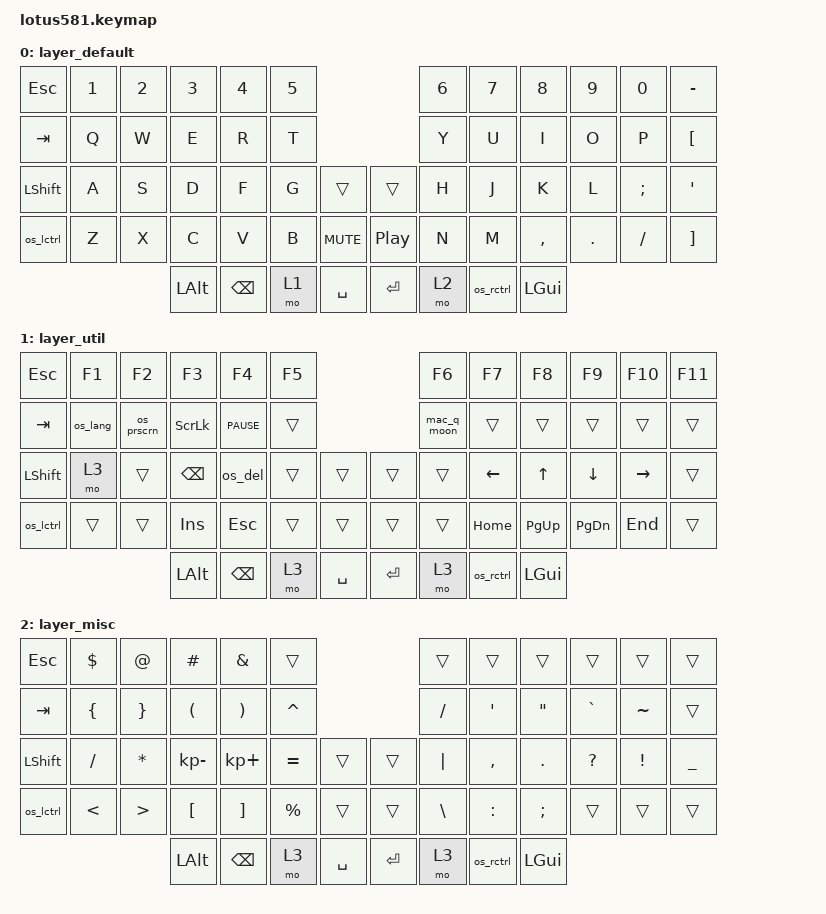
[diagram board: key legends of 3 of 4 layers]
/*
 * Copyright (c) 2022 The ZMK Contributors
 *
 * SPDX-License-Identifier: MIT
 */

#include <behaviors.dtsi>
#include <os_layer.dtsi>
#include <dt-bindings/zmk/keys.h>
#include <dt-bindings/zmk/bt.h>
#include <dt-bindings/zmk/outputs.h>
#include <dt-bindings/zmk/rgb.h>
#include <dt-bindings/led/led.h>
#include <dt-bindings/zmk/os_layer_defines.h>

/ {
    macros {
        sw_p_w: ctrl_shift_l_macro {
            compatible = "zmk,behavior-macro";
            #binding-cells = <0>;
            bindings = <&macro_press &kp LCTRL &kp LSHIFT>,
                       <&macro_tap &kp L>,
                       <&macro_release &kp LCTRL &kp LSHIFT>;
        };

        sw_n_w: ctrl_shift_k_macro {
            compatible = "zmk,behavior-macro";
            #binding-cells = <0>;
            bindings = <&macro_press &kp LCTRL &kp LSHIFT>,
                       <&macro_tap &kp K>,
                       <&macro_release &kp LCTRL &kp LSHIFT>;
        };

        mac_prscrn: mac_prscrn_macro {
            compatible = "zmk,behavior-macro";
            #binding-cells = <0>;
            bindings = <&macro_press &kp LEFT_GUI &kp LSHIFT>,
                       <&macro_tap &kp N5>,
                       <&macro_release &kp LEFT_GUI &kp LSHIFT>;
        };

        mac_del: mac_del_macro {
            compatible = "zmk,behavior-macro";
            #binding-cells = <0>;
            bindings = <&macro_press &kp LEFT_GUI>,
                       <&macro_tap &kp BSPC>,
                       <&macro_release &kp LEFT_GUI>;

        };

        mac_lang: mac_lang_macro {
            compatible = "zmk,behavior-macro";
            #binding-cells = <0>;
            bindings = <&macro_press &kp LCTRL>,
                       <&macro_tap &kp SPACE>,
                       <&macro_release &kp LCTRL>;
        };

        other_lang: other_lang_macro {
            compatible = "zmk,behavior-macro";
            #binding-cells = <0>;
            bindings = <&macro_press &kp LSHFT>,
                       <&macro_tap &kp LALT>,
                       <&macro_release &kp LSHFT>;
        };

        mac_q_moon: mac_q_moon_macro {
            compatible = "zmk,behavior-macro";
            #binding-cells = <0>;
            bindings = <&macro_press &kp LCTRL &kp LSHFT &kp LALT>,
                       <&macro_tap &kp Q>,
                       <&macro_release &kp LCTRL &kp LSHFT &kp LALT>;
        };
    };

    behaviors {
        rgb_encoder: rgb_encoder {
            compatible = "zmk,behavior-sensor-rotate";
            #sensor-binding-cells = <0>;
            bindings = <&rgb_ug RGB_BRI>, <&rgb_ug RGB_BRD>;
        };

        os_lctrl: os_lctrl {
            compatible = "zmk,behavior-os-mod";
            #binding-cells = <0>;
            bindings = <&os_choose KP_OS_OTHER &kp LCTRL>,
                        <&os_choose KP_OS_MAC &kp LEFT_GUI>;
        };

        os_rctrl: os_rctrl {
            compatible = "zmk,behavior-os-mod";
            #binding-cells = <0>;
            bindings = <&os_choose KP_OS_OTHER &kp RSHIFT>,
                        <&os_choose KP_OS_MAC &kp LCTRL>;
        };

        os_prscrn: os_prscrn {
            compatible = "zmk,behavior-os-mod";
            #binding-cells = <0>;
            bindings = <&os_choose KP_OS_OTHER &kp PSCRN>,
                        <&os_choose KP_OS_MAC &mac_prscrn>;
        };

        os_del: os_del {
            compatible = "zmk,behavior-os-mod";
            #binding-cells = <0>;
            bindings = <&os_choose KP_OS_OTHER &kp DELETE>,
                        <&os_choose KP_OS_MAC &mac_del>;
        };

        os_lang: os_lang {
            compatible = "zmk,behavior-os-mod";
            #binding-cells = <0>;
            bindings = <&os_choose KP_OS_OTHER &other_lang>,
                        <&os_choose KP_OS_MAC &mac_lang>;
        };
    };

    keymap {
        compatible = "zmk,keymap";

        layer_default {
            bindings = <
&kp ESC   &kp N1 &kp N2   &kp N3     &kp N4    &kp N5                               &kp N6    &kp N7      &kp N8    &kp N9   &kp N0   &kp MINUS
&kp TAB   &kp Q  &kp W    &kp E      &kp R     &kp T                                &kp Y     &kp U       &kp I     &kp O    &kp P    &kp LEFT_BRACKET
&kp LSHFT &kp A  &kp S    &kp D      &kp F     &kp G      &trans         &trans     &kp H     &kp J       &kp K     &kp L    &kp SEMI &kp SINGLE_QUOTE
&os_lctrl &kp Z  &kp X    &kp C      &kp V     &kp B      &kp K_MUTE     &kp C_PP   &kp N     &kp M       &kp COMMA &kp DOT  &kp SLASH &kp RIGHT_BRACKET
                          &kp LALT   &kp BSPC  &mo 1 &kp SPACE     &kp ENTER  &mo 2  &os_rctrl  &kp LEFT_GUI
            >;

            sensor-bindings = <&inc_dec_kp &sw_p_w &sw_n_w &inc_dec_kp DOWN_ARROW UP_ARROW>;
        };

         layer_util {
            bindings = <
&kp ESC   &kp F1    &kp F2    &kp F3    &kp F4    &kp F5                                &kp F6    &kp F7    &kp F8    &kp F9    &kp F10   &kp F11
&kp TAB   &os_lang    &os_prscrn &kp SLCK  &kp C_PAUSE &trans                                &mac_q_moon    &trans    &trans    &trans    &trans    &trans
&kp LSHFT &mo 3     &trans    &kp BSPC  &os_del &trans   &trans            &trans    &trans    &kp LEFT  &kp UP    &kp DOWN  &kp RIGHT &trans
&os_lctrl &trans    &trans    &kp INSERT &kp ESCAPE &trans  &trans            &trans    &trans    &kp HOME  &kp PAGE_UP &kp PAGE_DOWN &kp END &trans
                              &kp LALT  &kp BSPC  &mo 3     &kp SPACE         &kp ENTER &mo 3     &os_rctrl &kp LEFT_GUI
            >;

            sensor-bindings = <&inc_dec_kp C_VOL_DN C_VOL_UP &inc_dec_kp C_PREV C_NEXT>;
        };

        layer_misc {
            bindings = <
&kp ESC   &kp DLLR     &kp AT      &kp HASH        &kp AMPS       &trans                                   &trans       &trans              &trans        &trans       &trans       &trans
&kp TAB   &kp LBRC     &kp RBRC    &kp LPAR        &kp RPAR       &kp CARET                                &kp SLASH    &kp SINGLE_QUOTE    &kp DQT       &kp GRAVE    &kp TILDE    &trans
&kp LSHFT &kp FSLH     &kp STAR    &kp KP_MINUS    &kp KP_PLUS    &kp EQUAL    &trans            &trans    &kp PIPE     &kp COMMA           &kp PERIOD    &kp QMARK    &kp EXCL     &kp UNDER
&os_lctrl &kp LT       &kp GT      &kp LBKT        &kp RBKT       &kp PERCENT  &trans            &trans    &kp BSLH     &kp COLON           &kp SEMI      &trans       &trans       &trans
                           &kp LALT  &kp BSPC   &mo 3                          &kp SPACE         &kp ENTER         &mo 3     &os_rctrl &kp LEFT_GUI
            >;

            sensor-bindings = <&inc_dec_kp C_VOL_DN C_VOL_UP &inc_dec_kp PG_UP PG_DN>;
        };  

        layer_settings {
            bindings = <
&out OUT_TOG    &trans    &trans    &rgb_ug RGB_EFF &rgb_ug RGB_HUD  &rgb_ug RGB_HUI                                &bt BT_SEL 0   &bt BT_SEL 1    &bt BT_SEL 2    &trans    &trans    &bt BT_CLR
&trans          &trans    &trans    &rgb_ug RGB_EFR &rgb_ug RGB_SAD  &rgb_ug RGB_SAI                                &os_sel GO_LINUX_OS  &os_sel GO_NEXT_OS          &trans          &trans    &trans    &trans
&trans          &trans    &trans    &trans          &rgb_ug RGB_BRD  &rgb_ug RGB_BRI    &trans            &trans    &os_sel GO_MAC_OS    &os_sel GO_PREV_OS          &trans          &trans    &trans    &trans
&trans          &trans    &trans    &rgb_ug RGB_TOG &rgb_ug RGB_SPD  &rgb_ug RGB_SPI    &trans            &trans    &os_sel GO_WIN_OS    &trans          &trans          &trans    &trans    &trans
                    &trans    &trans        &trans        &trans        &trans            &trans    &trans    &trans    &trans    &trans
            >;

            sensor-bindings = <&rgb_encoder &inc_dec_kp C_NEXT C_PREV>;
        };
    };
};
